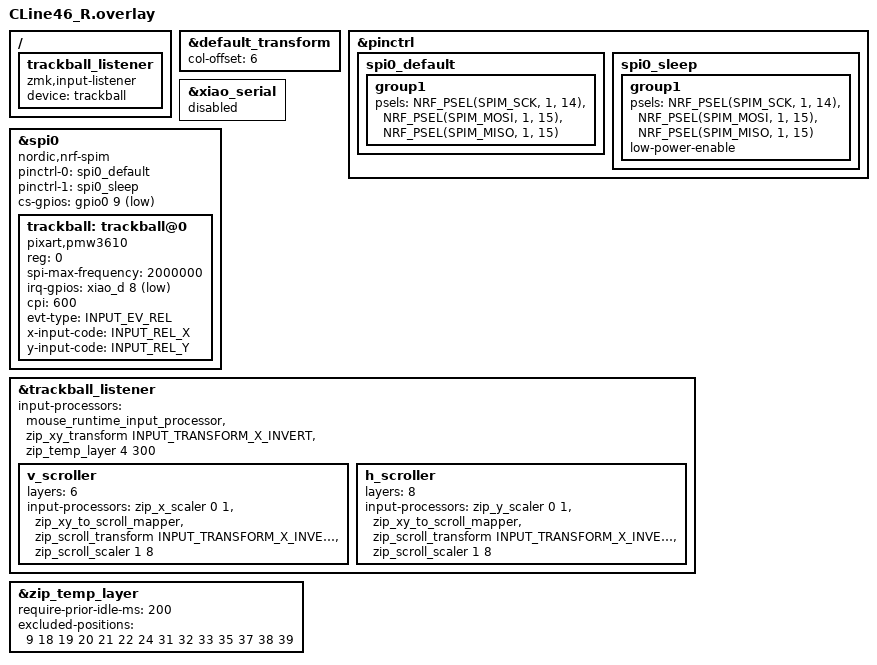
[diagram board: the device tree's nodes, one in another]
#include "CLine46.dtsi"
#include <zephyr/dt-bindings/input/input-event-codes.h>
#include <input/processors.dtsi>
#include <input/processors/runtime-input-processor.dtsi>
#include <behaviors/battery_history_request.dtsi>

&default_transform {
    col-offset = <6>;
};


/ {
    trackball_listener {
        status = "okay";
        compatible = "zmk,input-listener";
        device = <&trackball>;
    };
};

&pinctrl {
    spi0_default: spi0_default {
        group1 {
            psels = <NRF_PSEL(SPIM_SCK, 1, 14)>,
                <NRF_PSEL(SPIM_MOSI, 1, 15)>,
                <NRF_PSEL(SPIM_MISO, 1, 15)>;
        };
    };

    spi0_sleep: spi0_sleep {
        group1 {
            psels = <NRF_PSEL(SPIM_SCK, 1, 14)>,
                <NRF_PSEL(SPIM_MOSI, 1, 15)>,
                <NRF_PSEL(SPIM_MISO, 1, 15)>;
            low-power-enable;
        };
    };
};


&xiao_serial { status = "disabled"; };

&spi0 {
    status = "okay";
    compatible = "nordic,nrf-spim";
    pinctrl-0 = <&spi0_default>;
    pinctrl-1 = <&spi0_sleep>;
    pinctrl-names = "default", "sleep";
    cs-gpios = <&gpio0 9 GPIO_ACTIVE_LOW>;  //P0.09を指定(CS)

    trackball: trackball@0 {
        status = "okay";
        compatible = "pixart,pmw3610";
        reg = <0>;
        spi-max-frequency = <2000000>;
        irq-gpios = <&xiao_d 8 (GPIO_ACTIVE_LOW | GPIO_PULL_UP)>;
        cpi = <600>;
        //swap-xy;
        evt-type = <INPUT_EV_REL>;
        x-input-code = <INPUT_REL_X>;
        y-input-code = <INPUT_REL_Y>;
    };
};

// Overrides for the input listener node
&trackball_listener {
    status = "okay";
    input-processors =<&mouse_runtime_input_processor>,
        //<&zip_xy_transform INPUT_TRANSFORM_Y_INVERT>,       //Y軸反転
        //<&zip_xy_transform INPUT_TRANSFORM_XY_SWAP>,        //X軸とY軸の入れ替え
        <&zip_xy_transform INPUT_TRANSFORM_X_INVERT>,       //X軸反転
        <&zip_temp_layer 4 300>;                            //オートマウスレイヤー(AML=レイヤー4)を300ms有効化


    // 縦スクロール専用（VSCROLL=レイヤー6）。
    // 片軸を 0 倍で潰す構成のため、コメントアウトされた候補行を有効化するときは
    // どちらの軸が潰されるかも見直すこと。候補行は zip_x_scaler より前に適用される。
    // - X_INVERT: 直後に X が 0 になるため効かない
    // - XY_SWAP: mapper に入る前に軸コードが入れ替わるため、zip_x_scaler 0 1 が潰すのは
    //   「入れ替え後の X」＝元の Y になる。縦スクロール自体は生き残り、駆動が
    //   ボールの上下から左右に変わるだけ（scaler の差し替えは不要）。実機未検証
    v_scroller {
        layers = <6>;
        input-processors =
            // <&zip_xy_transform INPUT_TRANSFORM_XY_SWAP>,        //X軸とY軸の入れ替え
            // <&zip_xy_transform INPUT_TRANSFORM_X_INVERT>,       //X軸反転
            //<&zip_xy_transform INPUT_TRANSFORM_Y_INVERT>,       //Y軸反転
            <&zip_x_scaler 0 1>,                                //横成分を捨てる(縦スクロール専用)
            <&zip_xy_to_scroll_mapper>,                         //スクロールモードに変更
            <&zip_scroll_transform INPUT_TRANSFORM_X_INVERT>,   //横成分が0のため実効なし(全方向へ戻すとき用に温存)
            //<&zip_scroll_transform INPUT_TRANSFORM_Y_INVERT>,   //スクロールのY軸反転
            <&zip_scroll_scaler 1 8>;                           //スクロール量を1/8倍
    };

    // 横スクロール専用（HSCROLL=レイヤー8）。
    // レイヤー6と8が同時に有効になるのは、位置9(&mo 8)を保持したまま位置21を押したとき
    // （HSCROLL は全 &trans なので、AML が有効な間は AML の &mo 6 に落ちる）。挙動は未確認。
    // 逆順は成立しない（VSCROLL の位置9 は &kp NUMBER_9 で &mo 8 に届かない）。
    h_scroller {
        layers = <8>;
        input-processors =
            <&zip_y_scaler 0 1>,                                //縦成分を捨てる(横スクロール専用)
            <&zip_xy_to_scroll_mapper>,                         //スクロールモードに変更
            <&zip_scroll_transform INPUT_TRANSFORM_X_INVERT>,   //スクロールのX軸反転(向きを変えるならこの行を外す)
            <&zip_scroll_scaler 1 8>;                           //スクロール量を1/8倍
    };
};

&zip_temp_layer {
    require-prior-idle-ms = <200>;
    excluded-positions = <
        9   // HSCROLL レイヤー呼び出し (AML)
        18  // Shift+Ctrl+Tab (AML)
        19  // MB1 (AML)
        20  // MB2 (AML)
        21  // VSCROLL レイヤー呼び出し (AML)
        22  // Ctrl+Tab (AML)
        24  // Left_Shift
        31  // Ctrl+F4 (AML)
        32  // Alt+Left (AML)
        33  // Alt+Right (AML)
        35  // Right_Shift
        37  // Left_Win
        38  // Left_Alt
        39  // Left_Control
    >;
};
